# CW32L031 register map
Vendor: Wuhan Xinyuan Semiconductor Co.,Ltd; Series: CW32L031xx; File version: 1.2
CPU: CM0+ r0p1, little endian, no MPU, no FPU, 3 interrupt priority bits
Registers are 32-bit, read-write, no defined reset value unless marked. A register's access mark holds for its fields unless they carry their own. Offsets are from the block's base; [hi:lo] are bit positions; {n}, {i} and the like mark numbered series; 'fields as' and 'values as' point back to an identical list.

## I2C1
Base 0x40005400
0x00 BRREN
  [0] EN
0x04 BRR
  [7:0] BRR
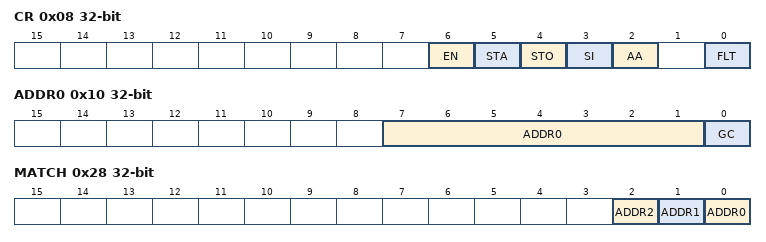
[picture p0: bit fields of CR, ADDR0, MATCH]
0x08 CR
  [6] EN, [5] STA, [4] STO, [3] SI, [2] AA, [0] FLT
0x0C DR
  [7:0] DR
0x10 ADDR0
  [7:1] ADDR0, [0] GC
0x14 STAT ro
  [7:0] STAT
0x20 ADDR1
  [7:1] ADDR1
0x24 ADDR2
  [7:1] ADDR2
0x28 MATCH ro
  [2] ADDR2, [1] ADDR1, [0] ADDR0

## IWDT
Base 0x40003000
0x00 KR wo
  [15:0] KR
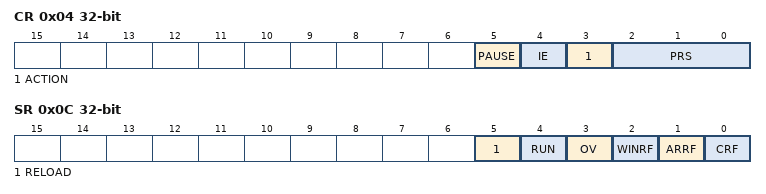
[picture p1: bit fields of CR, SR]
0x04 CR
  [5] PAUSE, [4] IE, [3] ACTION, [2:0] PRS
0x08 ARR
  [11:0] ARR
0x0C SR
  [5] RELOAD ro, [4] RUN ro, [3] OV, [2] WINRF ro, [1] ARRF ro, [0] CRF ro
0x10 WINR
  [11:0] WINR
0x24 CNT ro
  [11:0] CNT

## LVD
Base 0x40012A80
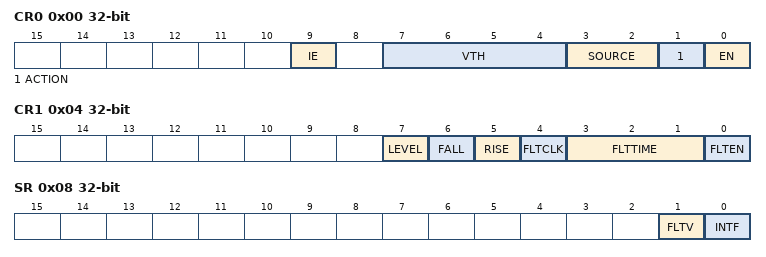
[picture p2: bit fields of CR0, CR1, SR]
0x00 CR0
  [9] IE, [7:4] VTH, [3:2] SOURCE, [1] ACTION, [0] EN
0x04 CR1
  [7] LEVEL, [6] FALL, [5] RISE, [4] FLTCLK, [3:1] FLTTIME, [0] FLTEN
0x08 SR
  [1] FLTV ro, [0] INTF

## RAM
Base 0x40022400
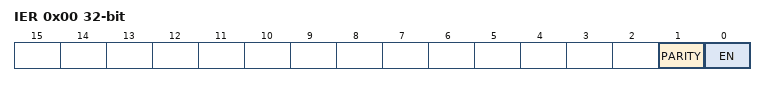
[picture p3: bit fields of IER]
0x00 IER
  [1] PARITY, [0] EN
0x04 ADDR ro
  [13:0] ADDR
0x08 ISR ro
  [0] PARITY
0x0C ICR
  [0] PARITY

## RTC
Base 0x40002800
0x00 KEY wo
  [7:0] KEY
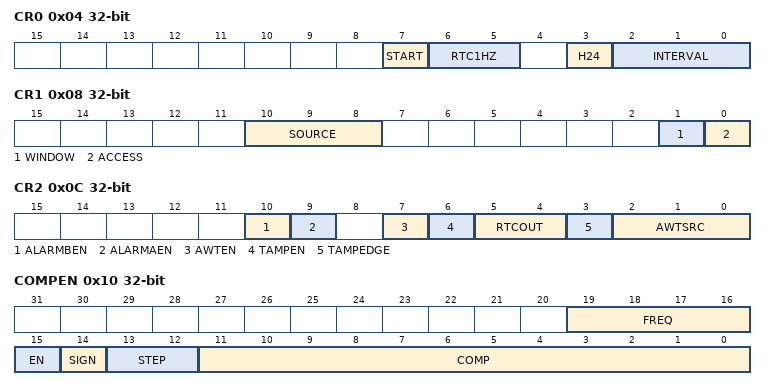
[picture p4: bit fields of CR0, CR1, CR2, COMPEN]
0x04 CR0
  [7] START
  [6:5] RTC1HZ
  [3] H24 — desc AMPM
  [2:0] INTERVAL
0x08 CR1
  [10:8] SOURCE, [1] WINDOW ro, [0] ACCESS
0x0C CR2
  [10] ALARMBEN, [9] ALARMAEN, [7] AWTEN, [6] TAMPEN, [5:4] RTCOUT, [3] TAMPEDGE, [2:0] AWTSRC
0x10 COMPEN
  [19:16] FREQ, [15] EN, [14] SIGN, [13:12] STEP, [11:0] COMP
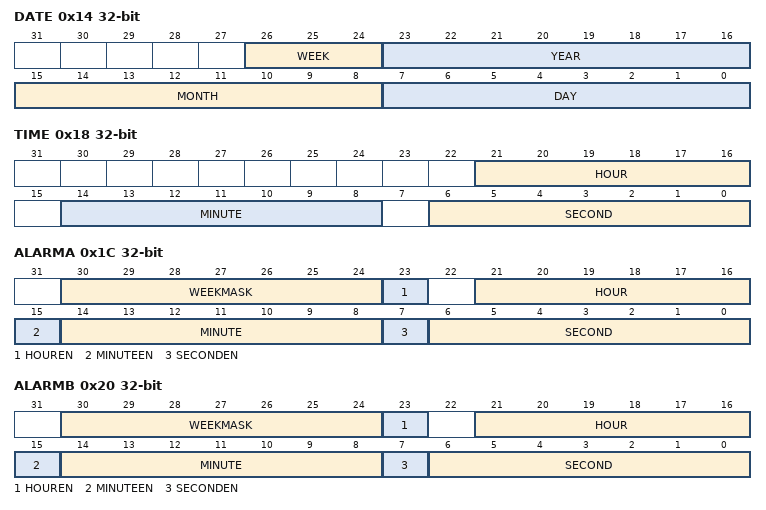
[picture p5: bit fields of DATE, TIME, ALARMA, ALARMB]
0x14 DATE
  [26:24] WEEK, [23:16] YEAR, [15:8] MONTH, [7:0] DAY
0x18 TIME
  [21:16] HOUR, [14:8] MINUTE, [6:0] SECOND
0x1C ALARMA
  [30:24] WEEKMASK, [23] HOUREN, [21:16] HOUR, [15] MINUTEEN, [14:8] MINUTE, [7] SECONDEN, [6:0] SECOND
0x20 ALARMB
  fields as ALARMA
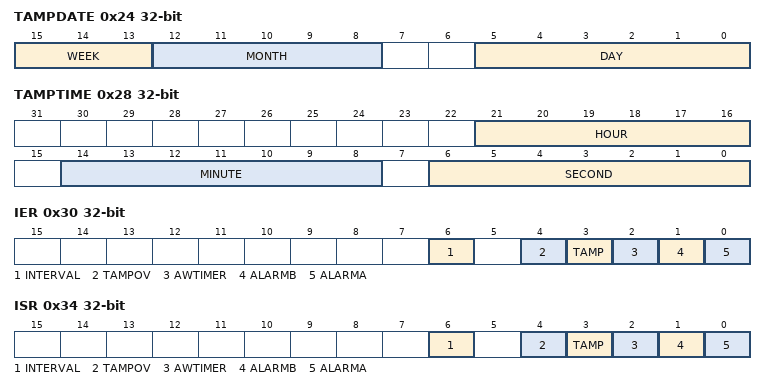
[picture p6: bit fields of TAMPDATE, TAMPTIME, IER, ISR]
0x24 TAMPDATE ro
  [15:13] WEEK, [12:8] MONTH, [5:0] DAY
0x28 TAMPTIME ro
  [21:16] HOUR, [14:8] MINUTE, [6:0] SECOND
0x2C AWTARR
  [15:0] ARR
0x30 IER
  [6] INTERVAL, [4] TAMPOV, [3] TAMP, [2] AWTIMER, [1] ALARMB, [0] ALARMA
0x34 ISR ro
  fields as IER
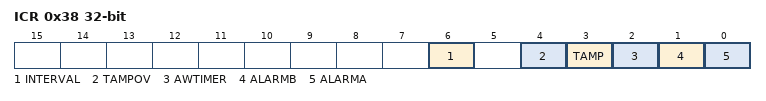
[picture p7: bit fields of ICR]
0x38 ICR
  fields as IER

## SPI1
Base 0x40013000
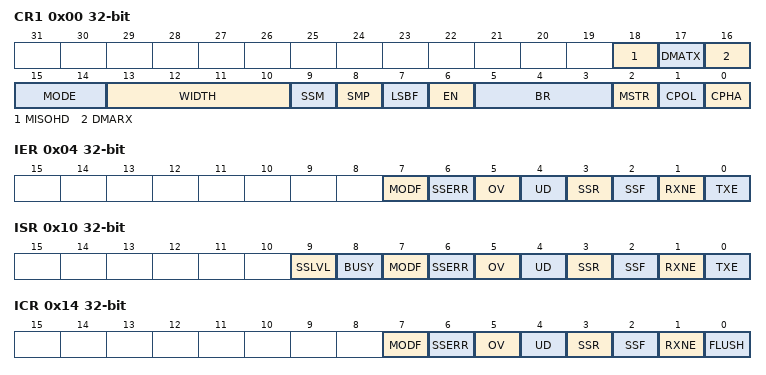
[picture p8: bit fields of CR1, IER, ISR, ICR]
0x00 CR1
  [18] MISOHD, [17] DMATX, [16] DMARX, [15:14] MODE, [13:10] WIDTH, [9] SSM, [8] SMP, [7] LSBF, [6] EN, [5:3] BR, [2] MSTR, [1] CPOL, [0] CPHA
0x04 IER
  [7] MODF, [6] SSERR, [5] OV, [4] UD, [3] SSR, [2] SSF, [1] RXNE, [0] TXE
0x08 CR2
  [0] HDOE
0x0C SSI
  [0] SSI
0x10 ISR ro
  [9] SSLVL, [8] BUSY, [7] MODF, [6] SSERR, [5] OV, [4] UD, [3] SSR, [2] SSF, [1] RXNE, [0] TXE
0x14 ICR
  [7] MODF, [6] SSERR, [5] OV, [4] UD, [3] SSR, [2] SSF, [1] RXNE, [0] FLUSH
0x18 DR
  [15:0] DR

## SYSCTRL
Base 0x40010000
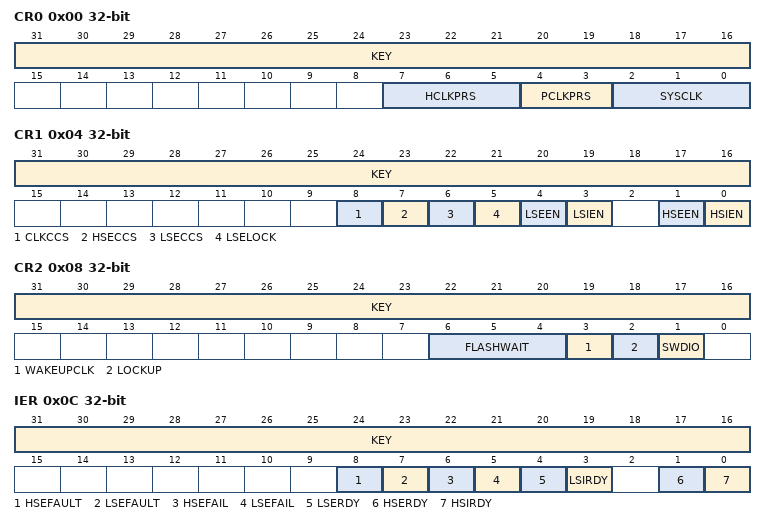
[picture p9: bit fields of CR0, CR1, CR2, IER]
0x00 CR0
  [31:16] KEY wo, [7:5] HCLKPRS, [4:3] PCLKPRS, [2:0] SYSCLK
0x04 CR1
  [31:16] KEY wo, [8] CLKCCS, [7] HSECCS, [6] LSECCS, [5] LSELOCK, [4] LSEEN, [3] LSIEN, [1] HSEEN, [0] HSIEN
0x08 CR2
  [31:16] KEY wo, [6:4] FLASHWAIT, [3] WAKEUPCLK, [2] LOCKUP, [1] SWDIO
0x0C IER
  [31:16] KEY wo, [8] HSEFAULT, [7] LSEFAULT, [6] HSEFAIL, [5] LSEFAIL, [4] LSERDY, [3] LSIRDY, [1] HSERDY, [0] HSIRDY
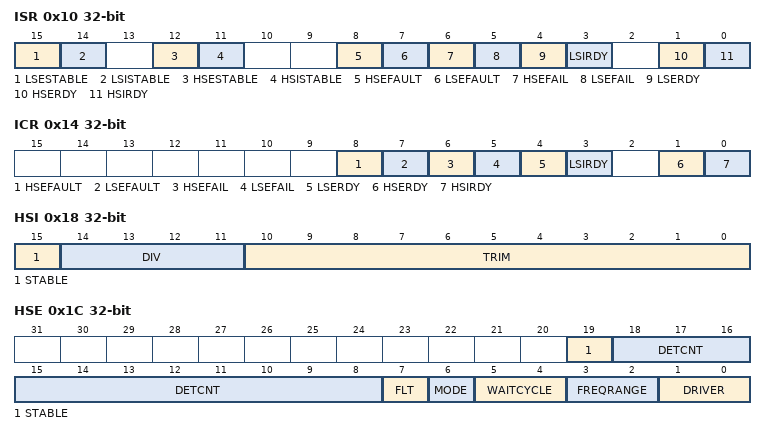
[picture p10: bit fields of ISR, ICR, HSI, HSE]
0x10 ISR ro
  [15] LSESTABLE, [14] LSISTABLE, [12] HSESTABLE, [11] HSISTABLE, [8] HSEFAULT, [7] LSEFAULT, [6] HSEFAIL, [5] LSEFAIL, [4] LSERDY, [3] LSIRDY, [1] HSERDY, [0] HSIRDY
0x14 ICR
  [8] HSEFAULT, [7] LSEFAULT, [6] HSEFAIL, [5] LSEFAIL, [4] LSERDY, [3] LSIRDY, [1] HSERDY, [0] HSIRDY
0x18 HSI
  [15] STABLE ro, [14:11] DIV, [10:0] TRIM
0x1C HSE
  [19] STABLE ro, [18:8] DETCNT, [7] FLT, [6] MODE, [5:4] WAITCYCLE, [3:2] FREQRANGE, [1:0] DRIVER
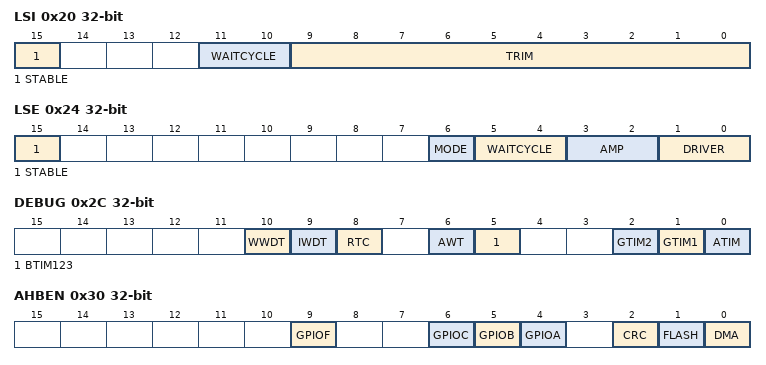
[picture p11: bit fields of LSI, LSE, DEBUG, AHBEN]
0x20 LSI
  [15] STABLE ro, [11:10] WAITCYCLE, [9:0] TRIM
0x24 LSE
  [15] STABLE ro, [6] MODE, [5:4] WAITCYCLE, [3:2] AMP, [1:0] DRIVER
0x2C DEBUG
  [10] WWDT, [9] IWDT, [8] RTC, [6] AWT, [5] BTIM123, [2] GTIM2, [1] GTIM1, [0] ATIM
0x30 AHBEN
  [9] GPIOF, [6] GPIOC, [5] GPIOB, [4] GPIOA, [2] CRC, [1] FLASH, [0] DMA
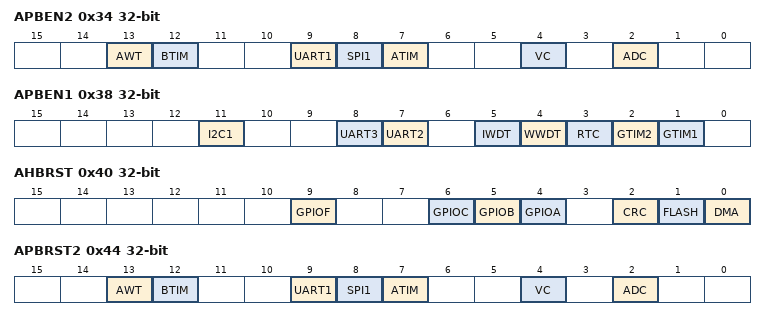
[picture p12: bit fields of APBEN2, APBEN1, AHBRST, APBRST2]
0x34 APBEN2
  [13] AWT, [12] BTIM, [9] UART1, [8] SPI1, [7] ATIM, [4] VC, [2] ADC
0x38 APBEN1
  [11] I2C1, [8] UART3, [7] UART2, [5] IWDT, [4] WWDT, [3] RTC, [2] GTIM2, [1] GTIM1
0x40 AHBRST
  fields as AHBEN
0x44 APBRST2
  [13] AWT, [12] BTIM, [9] UART1, [8] SPI1, [7] ATIM, [4] VC, [2] ADC
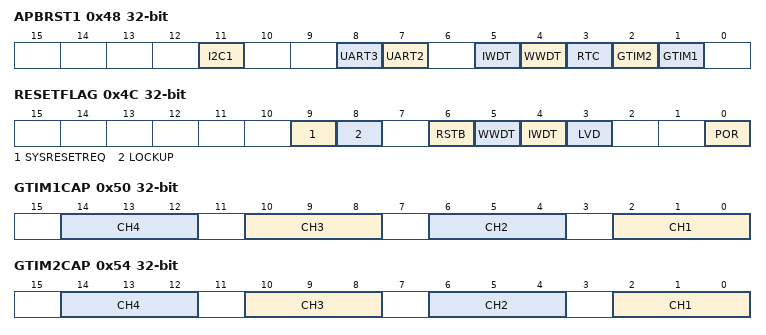
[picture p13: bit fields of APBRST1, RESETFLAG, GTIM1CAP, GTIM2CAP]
0x48 APBRST1
  fields as APBEN1
0x4C RESETFLAG
  [9] SYSRESETREQ, [8] LOCKUP, [6] RSTB, [5] WWDT, [4] IWDT, [3] LVD, [0] POR
0x50 GTIM1CAP
  [4n-2:4n-4] CH{n} (n=1..4)
0x54 GTIM2CAP
  [4n-2:4n-4] CH{n} (n=1..4)
0x60 ATIMETR
  [2:0] ATIMETR
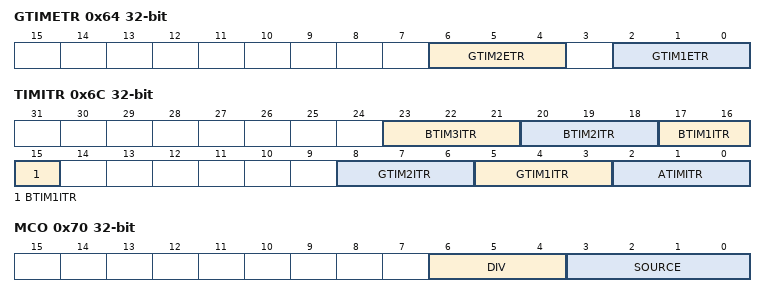
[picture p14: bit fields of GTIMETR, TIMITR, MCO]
0x64 GTIMETR
  [6:4] GTIM2ETR, [2:0] GTIM1ETR
0x6C TIMITR
  [23:21] BTIM3ITR, [20:18] BTIM2ITR, [17:15] BTIM1ITR, [8:6] GTIM2ITR, [5:3] GTIM1ITR, [2:0] ATIMITR
0x70 MCO
  [6:4] DIV, [3:0] SOURCE
0x74 IRMOD
  [3:0] MOD

## UART1
Base 0x40013800
Same registers: UART2 0x40004400, UART3 0x40004800
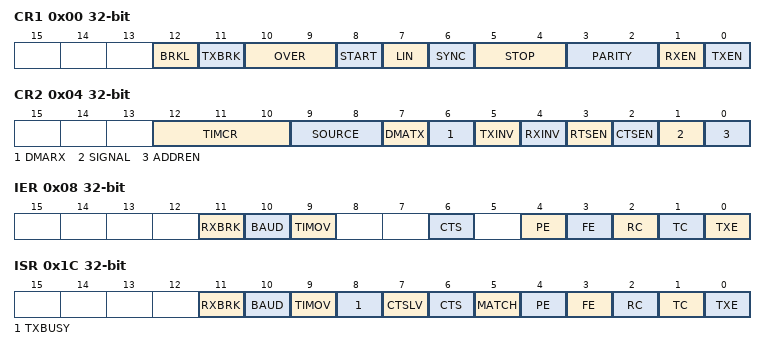
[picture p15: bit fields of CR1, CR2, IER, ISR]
0x00 CR1
  [12] BRKL — desc BRKLEN
  [11] TXBRK
  [10:9] OVER
  [8] START
  [7] LIN — desc LINEN
  [6] SYNC
  [5:4] STOP
  [3:2] PARITY
  [1] RXEN
  [0] TXEN
0x04 CR2
  [12:10] TIMCR, [9:8] SOURCE, [7] DMATX, [6] DMARX, [5] TXINV, [4] RXINV, [3] RTSEN, [2] CTSEN, [1] SIGNAL, [0] ADDREN
0x08 IER
  [11] RXBRK, [10] BAUD, [9] TIMOV, [6] CTS, [4] PE, [3] FE, [2] RC, [1] TC, [0] TXE
0x0C BRRI
  [15:0] BRRI
0x10 BRRF
  [3:0] BRRF
0x14 TIMARR
  [23:0] TIMARR
0x18 TIMCNT
  [23:0] TIMCNT
0x1C ISR ro
  [11] RXBRK, [10] BAUD, [9] TIMOV, [8] TXBUSY, [7] CTSLV, [6] CTS, [5] MATCH, [4] PE, [3] FE, [2] RC, [1] TC, [0] TXE
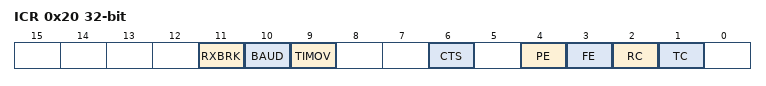
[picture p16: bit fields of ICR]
0x20 ICR
  [11] RXBRK, [10] BAUD, [9] TIMOV, [6] CTS, [4] PE, [3] FE, [2] RC, [1] TC
0x24 RDR ro
  [8:0] RDR
0x28 TDR wo
  [8:0] TDR
0x30 ADDR
  [7:0] ADDR
0x34 MASK
  [7:0] MASK

## VC1
Base 0x40012A00
Same registers: VC2 0x40012A10
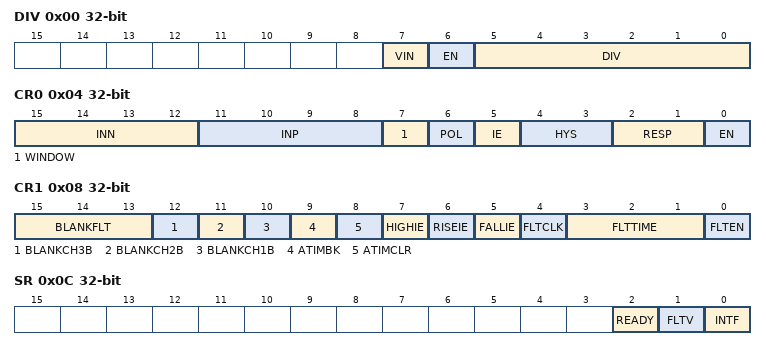
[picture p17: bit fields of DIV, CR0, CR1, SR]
0x00 DIV
  [7] VIN, [6] EN, [5:0] DIV
0x04 CR0
  [15:12] INN, [11:8] INP, [7] WINDOW, [6] POL, [5] IE, [4:3] HYS, [2:1] RESP, [0] EN
0x08 CR1
  [15:13] BLANKFLT, [12] BLANKCH3B, [11] BLANKCH2B, [10] BLANKCH1B, [9] ATIMBK, [8] ATIMCLR, [7] HIGHIE, [6] RISEIE, [5] FALLIE, [4] FLTCLK, [3:1] FLTTIME, [0] FLTEN
0x0C SR
  [2] READY ro, [1] FLTV ro, [0] INTF

## WWDT
Base 0x40002C00
0x00 CR0
  [7] EN, [6:0] WCNT
0x04 CR1
  [10] IE, [9:7] PRS, [6:0] WINR
0x08 SR
  [0] POV
